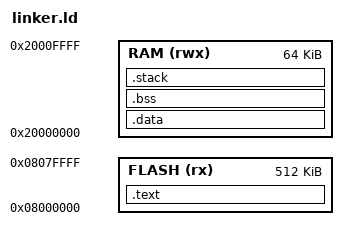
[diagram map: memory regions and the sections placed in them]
ENTRY(Reset_Handler)

MEMORY {
  FLASH (rx)  : ORIGIN = 0x08000000, LENGTH = 512K
  RAM   (rwx) : ORIGIN = 0x20000000, LENGTH = 64K
}

SECTIONS {
  .text : {
    KEEP(*(.isr_vector))
    *(.text*)
    *(.rodata*)
    _etext = .;
  } > FLASH

  .data : AT(_etext) {
    _sdata = .;
    *(.data*)
    _edata = .;
  } > RAM

  .bss : {
    _sbss = .;
    *(.bss*)
    *(COMMON)
    _ebss = .;
  } > RAM

  .stack (COPY) : {
    . = ALIGN(8);
    stack_start = .;
    . = . + 0x800;
    stack_end = .;
  } > RAM
}
